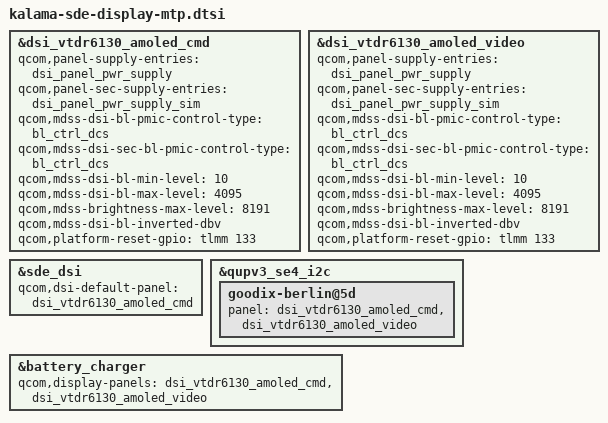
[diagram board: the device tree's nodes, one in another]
#include "kalama-sde-display.dtsi"

&dsi_vtdr6130_amoled_cmd {
	qcom,panel-supply-entries = <&dsi_panel_pwr_supply>;
	qcom,panel-sec-supply-entries = <&dsi_panel_pwr_supply_sim>;
	qcom,mdss-dsi-bl-pmic-control-type = "bl_ctrl_dcs";
	qcom,mdss-dsi-sec-bl-pmic-control-type = "bl_ctrl_dcs";
	qcom,mdss-dsi-bl-min-level = <10>;
	qcom,mdss-dsi-bl-max-level = <4095>;
	qcom,mdss-brightness-max-level = <8191>;
	qcom,mdss-dsi-bl-inverted-dbv;
	qcom,platform-reset-gpio = <&tlmm 133 0>;
};

&dsi_vtdr6130_amoled_video {
	qcom,panel-supply-entries = <&dsi_panel_pwr_supply>;
	qcom,panel-sec-supply-entries = <&dsi_panel_pwr_supply_sim>;
	qcom,mdss-dsi-bl-pmic-control-type = "bl_ctrl_dcs";
	qcom,mdss-dsi-sec-bl-pmic-control-type = "bl_ctrl_dcs";
	qcom,mdss-dsi-bl-min-level = <10>;
	qcom,mdss-dsi-bl-max-level = <4095>;
	qcom,mdss-brightness-max-level = <8191>;
	qcom,mdss-dsi-bl-inverted-dbv;
	qcom,platform-reset-gpio = <&tlmm 133 0>;
};

&sde_dsi {
	qcom,dsi-default-panel = <&dsi_vtdr6130_amoled_cmd>;
};

&qupv3_se4_i2c {
	goodix-berlin@5d {
		panel = <&dsi_vtdr6130_amoled_cmd
			&dsi_vtdr6130_amoled_video>;
	};
};

&battery_charger {
	qcom,display-panels = <&dsi_vtdr6130_amoled_cmd
			      &dsi_vtdr6130_amoled_video>;
};
